# vpac_targetdb register map
Vendor: Texas Instruments
Registers are 32-bit, read-write, no defined reset value unless marked. A register's access mark holds for its fields unless they carry their own. Offsets are as the file gives them; [hi:lo] are bit positions; {n}, {i} and the like mark numbered series; 'fields as' and 'values as' point back to an identical list.

## VPAC (part 2 of 8) — Vision Pre-Processing Accelerator (VPAC)
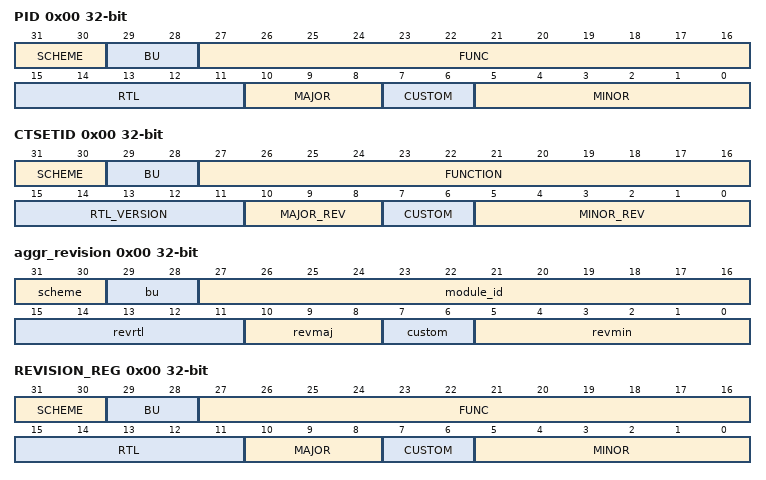
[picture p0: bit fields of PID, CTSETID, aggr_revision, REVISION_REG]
0x00 PID ro — VPAC PID
  [31:30] SCHEME — Used to distinguish between old scheme and new scheme. Spare bit to encode future schemes
  [29:28] BU — BU indicator
  [27:16] FUNC — Function indicates a software compatible module family.
  [15:11] RTL — RTL Version.
  [10:8] MAJOR — Major Revision.
  [7:6] CUSTOM — Indicates a special version for a particular device.
  [5:0] MINOR — Minor Revision.
0x00 REVISION ro
  [31:30] SCHEME
  [29:28] BU
  [27:16] FUNCTION — Module ID
  [15:11] RTLVER — RTL revisions
  [10:8] MAJREV — Major revision
  [7:6] CUSTOM — Custom revision
  [5:0] MINREV — Minor revision
{0x0+4i} pipeline_control_{i} (i=0..6) — Enable pipeline to activate all connected scheduler
  [0] pipe_en — Pipeline {i} enable, writing '1' activate pipeline , writing '0' during active pipeline is illegal and behavior is undefined, read '1' -> pipeline is active , read '0' -> pipeline is inactive
0x00 aggr_revision ro — Revision parameters
  [31:30] scheme
  [29:28] bu
  [27:16] module_id
  [15:11] revrtl — RTL version
  [10:8] revmaj — Major version
  [7:6] custom — Custom version
  [5:0] revmin — Minor version
0x00 CTSETID ro — CTSET identification register
  [31:30] SCHEME — Used to distinguish between old Scheme and current
  [29:28] BU — The value 10b designates this as Processor Business Unit IP
  [27:16] FUNCTION — Function : Indicates a Debug IP (0x2nn) and 0x80 is the identifier for CT-SET
  [15:11] RTL_VERSION — This field changes on bug fix, and resets to '0' when either Minor Revision or Major Revision field changes
  [10:8] MAJOR_REV — Major Revision. This field changes when there is a major feature change.
  [7:6] CUSTOM — Indicates a special version for a particular device. 0 if non-custom
  [5:0] MINOR_REV — Minor Revision. This field changes when features are scaled up or down
0x00 aggr_revision ro — Revision parameters
  fields as aggr_revision
0x00 REVISION_REG ro — LDC PID
  [31:30] SCHEME — Used to distinguish between old scheme and new scheme. Spare bit to encode future schemes
  [29:28] BU — BU indicatorDSPS ==> 0x0 WTBU ==> 0x1 Processors ==> 0x2
  [27:16] FUNC — Function indicates a software compatible module family. If there is no level of software compatibility a new FUNC number, and hence PID, should be assigned.
  [15:11] RTL — RTL Version. R as described in PDR with additional clarifications and definitions below. Must be easily ECO-able or controlled during fabrication. Ideally through a top level metal mask or e-fuse. This number is maintained/owned by IP design owner. RTL follows a numbering such as X.Y.R.Z which are explained in this table. R changes ONLY when: (1) PDS uploads occur which may have been due to spec changes (2) Bug fixes occur (3) Resets to '0' when X or Y changes. Design team has an internal 'Z' (customer invisible) number which increments on every drop that happens due to DV and RTL updates. Z resets to 0 when R increments.
  [10:8] MAJOR — Major Revision. X as described in PDR with additional clarifications/definitions below. This number is owned/maintained by IP specification owner. X is part of IP numbering X.Y.R.Z.X changes ONLY when: (1) There is a major feature addition. An example would be adding Master Mode to Utopia Level2. The Func field (or Class/Type in old PID format) will remain the same. X does NOT change due to: (1) Bug fixes (2) Change in feature parameters.
  [7:6] CUSTOM — Indicates a special version for a particular device. Consequence of use may avoid use of standard Chip Support Library (CSL) / Drivers. 0 if non-custom.
  [5:0] MINOR — Minor Revision. Y as described in PDR with additional clarifications/definitions below. This number is owned/maintained by IP specification owner. Y changes ONLY when: (1) Features are scaled (up or down). Flexibility exists in that this feature scalability may either be represented in the Y change or a specific register in the IP that indicates which features are exactly available. (2) When feature creeps from Is-Not list to Is list. But this may not be the case once it sees silicon - in which case X will change. Y does NOT change due to: (1) Bug fixes (2) Typos or clarifications (3) major functional/feature change/addition/deletion. Instead these changes may be reflected via R, S, X as applicable. Spec owner maintains a customer-invisible number 'S' which changes due to: (1) Typos/clarifications (2) Bug documentation. Note that this bug is not due to a spec change but due to implementation. Nevertheless, the spec tracks the IP bugs. An RTL release (say for silicon PG1.1) that occurs due to bug fix should document the corresponding spec number (X.Y.S) in its release notes.
0x00 status_param ro — The STATUS_PARAM register returns the LSE compile configuration parameters.
  [31:30] BYPASS_CH — Number of available input channel selection for loopback mode
  [29] OUT_SKIP_EN — Output Auto-Skip Enable
  [28] CORE_OUT_2D — 1D or 2D output addressing mode(2D if 1)
  [27:23] CORE_OUT_DW — Core Output Channel Data Width
  [22] LINE_SKIP_EN — Source Line Inc by 2 Supported (if 1)
  [21] BIT_AOFFSET — Source nibble offset address Supported (if 1)
  [20] HV_INSERT — H/VBLANK Insertion Supported (if 1)
  [19:17] PIX_MX_HT — Core_Input Pixel Matrix Height
  [16:12] CORE_DW — Core Input Data Bus Width
  [11:10] SL2_OUT_H3A_CH — Number of SL2 H3A Output Channels
  [9:6] SL2_OUT_CH — Number of SL2 Output Channels
  [5:3] SL2_IN_CH_THR — Number of Input Channels per thread
  [2] VPORT_THR — Number of VPORT input enabled
  [1:0] NTHR — Number of threads supported
0x00 LUT — dualy width conversion LUT
  [27:16] LUT_1 — Bank-1
  [11:0] LUT_0 — Bank-0
0x00 LUT — dualc width conversion LUT
  [27:16] LUT_1 — Bank-1
  [11:0] LUT_0 — Bank-0
0x00 RAM — mesh memory
  [31:0] MEM — Memory location
0x00 RAM access per field — y memory
  [23:0] MEM rw — Memory location
0x00 RAM access per field — cbcr memory
  [23:0] MEM rw — Memory location
0x00 aggr_revision ro — Revision parameters
  fields as aggr_revision
0x00 REVISION_REG ro — VISS PID
  fields as REVISION_REG
0x00 status_param ro — The STATUS_PARAM register returns the LSE compile configuration parameters.
  fields as status_param
0x00 GLBCE_CFG access per field — GLBCE Configuration Registers
  [0] SWRST rw — Reserved for this version for HW. This bit initiate software reset process
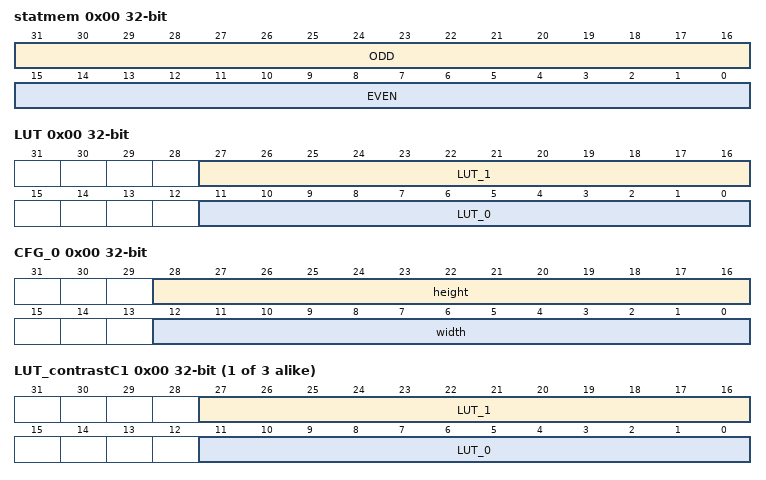
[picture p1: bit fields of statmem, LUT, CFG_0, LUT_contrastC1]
0x00 statmem — odd and even banks are combined for one 32-bit access
  [31:16] ODD — Odd bank
  [15:0] EVEN — Even bank
0x00 LUT — The LUT table contains the information used to reduce the pixle width to 12 from 13-16
  [27:16] lut_entry_hi — The upper LUT entry n+1.
  [11:0] lut_entry_lo — The lower LUT entry n+0.
0x00 CFG_0 access per field — The Control Register controls the input width and height of the module.
  [28:16] height rw — Height of the input image
  [12:0] width rw — Width of the input image
0x00 LUT_contrastC{i} access per field (i=1..3) — Memory for contrast C1
  [27:16] LUT_1 rw — Bank-1
  [11:0] LUT_0 rw — Bank-0
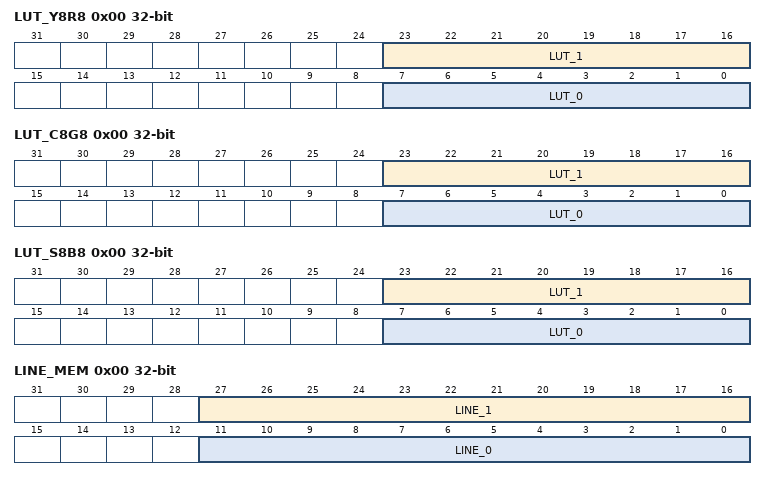
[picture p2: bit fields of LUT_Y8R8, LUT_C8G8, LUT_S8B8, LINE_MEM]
0x00 LUT_Y8R8 access per field — Memory for 12to8 LUT
  [23:16] LUT_1 rw — Bank-1
  [7:0] LUT_0 rw — Bank-0
0x00 LUT_C8G8 access per field — Memory for 12to8 LUT
  [23:16] LUT_1 rw — Bank-1
  [7:0] LUT_0 rw — Bank-0
0x00 LUT_S8B8 access per field — Memory for 12to8 LUT
  [23:16] LUT_1 rw — Bank-1
  [7:0] LUT_0 rw — Bank-0
0x00 HIST access per field — Memory for Histogram
  [19:0] HIST_VAL rw — Bank-0
0x00 LINE_MEM access per field — Memory for 2 lines of yuv444to420
  [27:16] LINE_1 rw, [11:0] LINE_0 rw
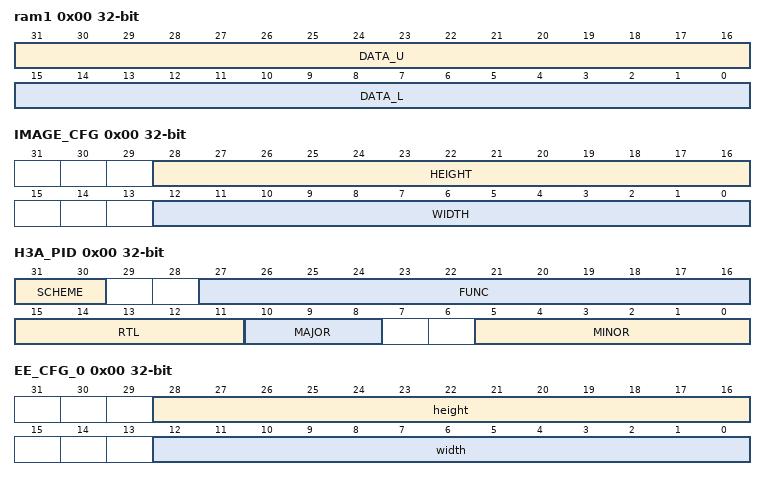
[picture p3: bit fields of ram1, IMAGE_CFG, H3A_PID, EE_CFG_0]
0x00 ram1 — Input image width and height.
  [31:16] DATA_U — reserved
  [15:0] DATA_L — reserved
0x00 ram1 — Input image width and height.
  [31:16] DATA_U — reserved
  [15:0] DATA_L — reserved
0x00 ram1 — Input image width and height.
  [31:16] DATA_U — reserved
  [15:0] DATA_L — reserved
0x00 ram1 — Input image width and height.
  [31:16] DATA_U — reserved
  [15:0] DATA_L — reserved
0x00 ram1 — Input image width and height.
  [25:16] DATA_U — reserved
  [9:0] DATA_L — reserved
0x00 ram1 — Input image width and height.
  [28:0] DATA — reserved
0x00 ram1 — Input image width and height.
  [31:0] DATA — reserved
0x00 ram1 — Input image width and height.
  [31:0] DATA — reserved
0x00 IMAGE_CFG access per field — Input image width and height.
  [28:16] HEIGHT rw — image height
  [12:0] WIDTH rw — image width
0x00 H3A_PID ro — Peripheral Revision and Class Information
  [31:30] SCHEME — PID scheme type
  [27:16] FUNC — PID func revision
  [15:11] RTL — PID rtl revision
  [10:8] MAJOR — PID major revision
  [5:0] MINOR — PID minor revision
0x00 ram1 — Input image width and height.
  [19:0] DATA — reserved
0x00 ram1 — Input image width and height.
  [31:0] DATA — reserved
0x00 DBG_MEM — Warning: reading or writing this MMR during operation will corrupt processing resulting in bad output data and will result in error interrupt firing. diagnostic rd/wr access to embedded RAM, for possible purpose of debugging failures
  [31:0] data — Adr range selects which RAM address to index. (Wr or rd beyond populated RAM adr result in non productive cycles and rd returns zero)
0x00 EE_CFG_0 — The Control Register controls the input width and height of the module.
  [28:16] height — Height of the input image
  [12:0] width — Width of the input image
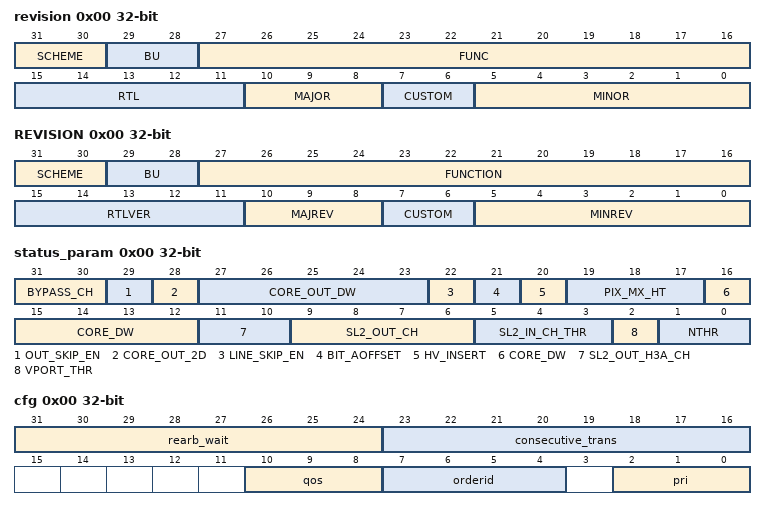
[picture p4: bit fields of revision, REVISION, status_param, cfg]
0x00 revision ro — The REVISION Register contains the major and minor revisions for the VPAC MSC HWA module.
  [31:30] SCHEME — Used to distinguish between old scheme and new scheme. Spare bit to encode future schemes
  [29:28] BU — BU indicatorDSPS ==> 0x0 WTBU ==> 0x1 Processors ==> 0x2
  [27:16] FUNC — Function indicates a software compatible module family. If there is no level of software compatibility a new FUNC number, and hence PID, should be assigned.
  [15:11] RTL — RTL Version. R as described in PDR with additional clarifications and definitions below. Must be easily ECO-able or controlled during fabrication. Ideally through a top level metal mask or e-fuse. This number is maintained/owned by IP design owner. RTL follows a numbering such as X.Y.R.Z which are explained in this table. R changes ONLY when : (1) PDS uploads occur which may have been due to spec changes (2) Bug fixes occur (3) Resets to '0' when X or Y changes. Design team has an internal 'Z' (customer invisible) number which increments on every drop that happens due to DV and RTL updates. Z resets to 0 when R increments.
  [10:8] MAJOR — Major Revision. X as described in PDR with additional clarifications/definitions below. This number is owned/maintained by IP specification owner. X is part of IP numbering X.Y.R.Z.X changes ONLY when: (1) There is a major feature addition. An example would be adding Master Mode to Utopia Level2. The Func field (or Class/Type in old PID format) will remain the same. X does NOT change due to: (1) Bug fixes (2) Change in feature parameters.
  [7:6] CUSTOM — Indicates a special version for a particular device. Consequence of use may avoid use of standard Chip Support Library (CSL) / Drivers. 0 if non-c ustom.
  [5:0] MINOR — Minor Revision. Y as described in PDR with additional clarifications/definitions below. This number is owned/maintained by IP specification owne r. Y changes ONLY when: (1) Features are scaled (up or down). Flexibility exists in that this feature scalability may either be represented in the Y change or a specific register in the IP that indica tes which features are exactly available. (2) When feature creeps from Is-Not list to Is list. But this may not be the case once it sees silicon - in which case X will change. Y does NOT change due to : (1) Bug fixes (2) Typos or clarifications (3) major functional/feature change/addition/deletion. Instead these changes may be reflected via R, S, X as applicable. Spec owner maintains a customer-invisible number 'S' which changes due to: (1) Typos/clarifications (2) Bug documentation. Note that this bug is not due to a spec change but due to implementation. Nevertheless, the spec tracks the I P bugs. An RTL release (say for silicon PG1.1) that occurs due to bug fix should document the corresponding spec number (X.Y.S) in its release notes.
0x00 status_param ro — The STATUS_PARAM register returns the LSE compile configuration parameters.
  fields as status_param
0x00 REVISION ro — The Revision Register contains the major and minor revisions for the module.
  [31:16] modid — Module ID field
  [15:11] revrtl — RTL revision. Will vary depending on release.
  [10:8] revmaj — Major revision
  [7:6] custom
  [5:0] revmin — Minor revision
0x00 status_param ro — The STATUS_PARAM register returns the LSE compile configuration parameters.
  fields as status_param
0x00 dru_pid ro — Peripheral ID Register
  [31:0] revision — PID Revision
0x00 dru_shared_evt_set access per field — DRU Shared Event Set Register
  [0] prot_err wo — Set the Prot Error event
0x00 cfg access per field — Configuration Register for Queue 0
  [31:24] rearb_wait rw — This is the number of commands that will be sent by other queues before allowing the queue to arbitrate again for the right to send commands. This is only started when a queue exhausted its consecutive trans count.
  [23:16] consecutive_trans rw — This is the number of consecutive transactions that will be sent before allowing another queue of equal level to arbitrate to send commands. This is the maximum number of commands that it can send. If the queue has any delays such as virtual address lookup then the arbitration will be forced regardless of the number of commands.
  [10:8] qos rw — This configures the QOS for QUEUE0. This should only be set for fixed priority queues and the lower queue should have the lower QoS.
  [7:4] orderid rw — This configures the orderid for QUEUE0.
  [2:0] pri rw — This configures the priority for QUEUE0. This will be the priority that will be presented on the External bus for all commands from this queue.
0x00 dru_pid ro — Peripheral ID Register
  [31:0] revision — PID Revision
0x00 dru_shared_evt_set access per field — DRU Shared Event Set Register
  [0] prot_err wo — Set the Prot Error event
0x00 cfg access per field — Configuration Register for Queue 0
  fields as cfg
0x00 pid ro — The Revision Register contains the major and minor revisions for the module.
  [31:30] scheme — PID register scheme
  [29:28] bu — Business Unit: 10 = Processors
  [27:16] func — Module ID
  [15:11] rtl — RTL revision. Will vary depending on release.
  [10:8] major — Major revision
  [7:6] custom
  [5:0] minor — Minor revision
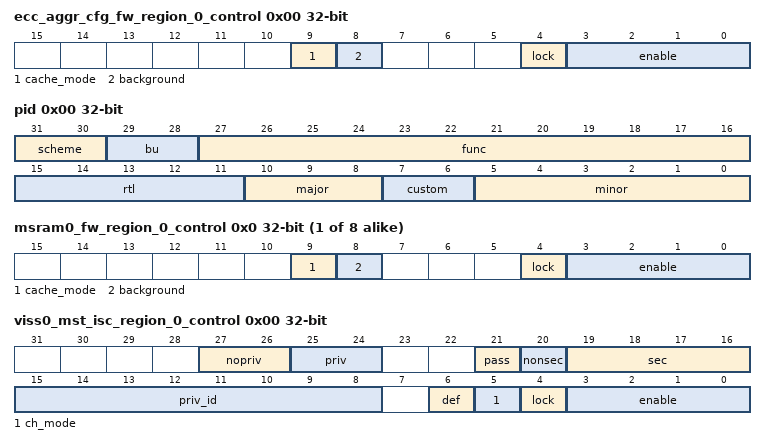
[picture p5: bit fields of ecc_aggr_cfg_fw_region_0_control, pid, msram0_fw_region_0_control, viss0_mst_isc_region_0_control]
0x00 ecc_aggr_cfg_fw_region_0_control — The FW Region 0 Control Register defines the control fields for the slave ksdw_ecc_aggr.cfg region 0 firewall.
  [9] cache_mode — Cache mode for region. Set to 1 to check cache permissions. Set to 0 to ignore cache permissions.
  [8] background — Background enable for region. There can be 1 backgroun region per FW and foreground regions can have overlapping addresses only with the background region.
  [4] lock — Lock region. Once set region values cannot be modified.
  [3:0] enable — Enable region. A value of 0xA enables, others disable.
0x00 pid ro — The Revision Register contains the major and minor revisions for the module.
  fields as pid
{0x0+0x20*i} msram0_fw_region_{i}_control (i=0..7) — The FW Region {i} Control Register defines the control fields for the slave ksbus_msram0.slv region {i} firewall.
  fields as ecc_aggr_cfg_fw_region_0_control
0x00 viss0_mst_isc_region_0_control access per field — The ISC Region 0 Control Register defines the control fields for the master .viss0_mst region 0 ISC.
  [27:26] nopriv rw — Clear output priv attribute. If each bit is set then the outgoing priv bit is cleared.
  [25:24] priv rw — Set outgoing priv attribute. If each bit is set then the outgoing priv bit is set.
  [21] pass rw — No privID replacement, pass through value.
  [20] nonsec rw — Make outgoing non-secure.
  [19:16] sec rw — Make outgoing secure. A value of 0xA enables, others disable.
  [15:8] priv_id rw
  [6] def ro — Default region indication. The default region is used when all other regions do not match.
  [5] ch_mode rw — Enable channel mode to match region to a chanid value. Otherwise use address mode to match region to an address range.
  [4] lock rw — Lock region. Once set the region values cannot be modified.
  [3:0] enable rw — Enable region. A value of 0xA enables, others disable.
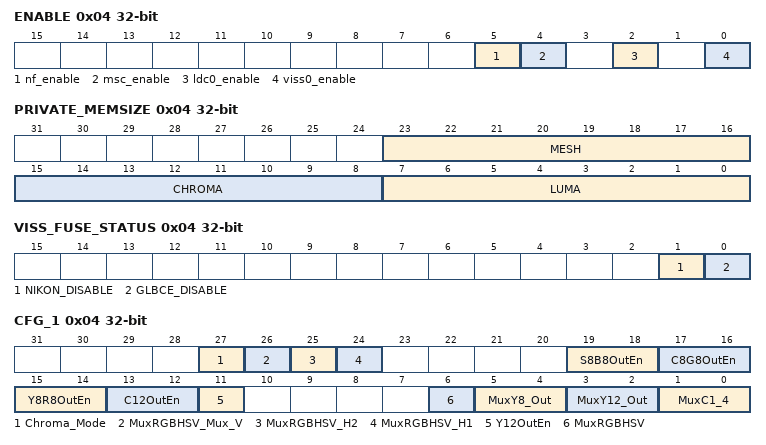
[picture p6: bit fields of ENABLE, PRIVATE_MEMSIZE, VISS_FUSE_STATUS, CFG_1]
0x04 ENABLE — VPAC accelerators Enable; used in clock gating accelerator when disabled. NOT SUPPORTED IN current VERSION
  [5] nf_enable — '1' --> nf is enabled , '0' --> nf is disabled
  [4] msc_enable — '1' --> msc is enabled , '0' --> msc is disabled
  [2] ldc0_enable — '1' --> ldc0 is enabled , '0' --> ldc0 is disabled
  [0] viss0_enable — '1' --> viss0 is enabled , '0' --> viss0 is disabled
0x04 PRIVATE_MEMSIZE ro — Memory size mentioned is for both ping and pong combined. Error interrupts are generated based on the memory size available.
  [23:16] MESH — Mesh Private pixel memory size in KBytes
  [15:8] CHROMA — Chroma Private pixel memory size in KBytes
  [7:0] LUMA — Luma Private pixel memory size in KBytes
0x04 status_error — The STATUS_ERROR register returns the LSE error status.
  [14:8] vm_wr_err — VBUSM I/F Last Write Error Status [14:11] Write Channel Number [10:8] VBUSM write error status
0x04 VISS_FUSE_STATUS ro — Register captures the Fuse control status. Shouldn't be captured into TRM
  [1] NIKON_DISABLE — Availability of NIKON specific feature HW in H3A. '0' -> Nikon features are available '1' -> Nikon features are not available
  [0] GLBCE_DISABLE — Availability GLBCE HW. '0' -> GLBCE function HW is available '1' -> GLBCE function HW is not available
0x04 status_error — The STATUS_ERROR register returns the LSE error status.
  [26:16] vport_in_err — VPORT_CAL Input Error Status Protocol Errors [26] VS without HS [25] VE without HE [24] VS-VS (missing VE) Error [23] HS-HS (missing HE) Error [22] HE-HE (missing HS) Error [21] VE-VE (missing VS) Error Frame Size Errors [20] Frame Skipped during Error Handling [19] Long Frame detected [18] Short Frame detected [17] Long Line detected [16] Short Line Detected
  [14:8] vm_wr_err — VBUSM I/F Last Write Error Status [14:11] Write Channel Number [10:8] VBUSM write error status
  [4:0] vm_rd_err — VBUSM I/F Last Read Error Status [4:3] Read Channel Number [2:0] VBUSM read error status
0x04 GLBCE_MODE access per field — GLBCE Mode Control register
  [0] OST rw — One shot mode or continuous mode One shot mode turns itself off after each frame Note that this bit only controls the enable signal, and does not revert the statistics to the default status To revert the cache content to the default status, you either need to SW reset GLBCE module, or load the default value from SDRAM to cache memory To perform the latter option, default cache table needs to be copied to SDRAM before hand
0x04 CFG_1 access per field — Configuration Register for top level data flow
  [27] Chroma_Mode rw — Mux for 422/420 (0:420 Chroma ,1: 422 Chroma)
  [26] MuxRGBHSV_Mux_V rw — Mux for V calculation (0:Select non WB corrected data ,1: Select WB corrected data)
  [25] MuxRGBHSV_H2 rw — Mux for S/V calculation (0:Select B,1: Select Max(RGB))
  [24] MuxRGBHSV_H1 rw — Mux for S/V calculation (0:Select R,1: Select Min(RGB))
  [19:18] S8B8OutEn rw — '0': Disable All , '1': S8 enable, 2:B8 enable, 3:C4 enable
  [17:16] C8G8OutEn rw — '0': Disable All , '1': C8 enable, 2:G8 enable, 3:C3 enable
  [15:14] Y8R8OutEn rw — '0': Disable all , '1': Y8 enable, 2:R8 enable, 3:C2 enable
  [13:12] C12OutEn rw — '0': Disable all , '1': C12 enable, '2': C1 enable
  [11] Y12OutEn rw — '0': Disable Y12 output, '1': Enable Y12 output
  [6] MuxRGBHSV rw — Input Select for RGBHSV (0:In after Contrast,1: In before Contrast)
  [5:4] MuxY8_Out rw — Mux for Y-8 Output (0:MuxC1_4, 1:RGB2YUV, 2:RGB2HSV)
  [3:2] MuxY12_Out rw — Mux for Y-12 Output (0:MuxC1_4, 1:RGB2YUV, 2:RGB2HSV, 3:C1 enable)
  [1:0] MuxC1_4 rw — Mux for selecting C input (0:C0, 1:C1, 2:C2, 3:C3)
0x04 SHADOW_CFG — shadow configuration
  [0] LUT3_SHDW_EN — use LUT2 ram as LUT table for LUT3 processing
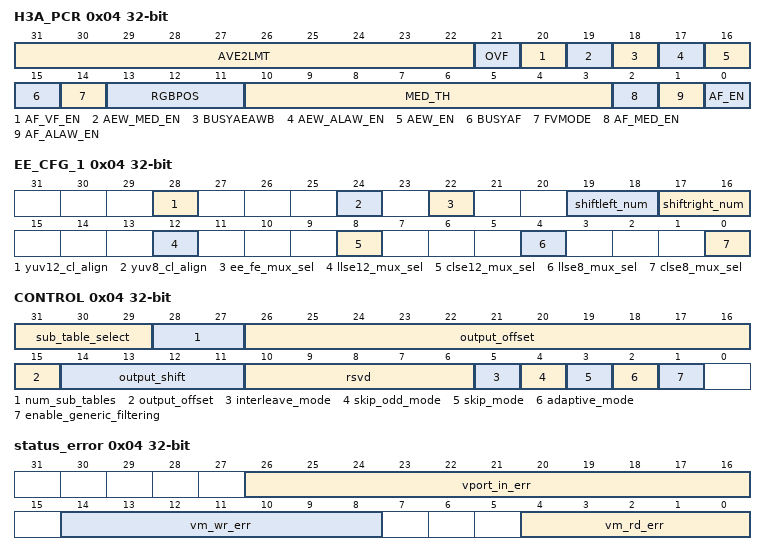
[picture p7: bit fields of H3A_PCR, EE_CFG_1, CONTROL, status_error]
0x04 H3A_PCR access per field — Peripheral Control Register
  [31:22] AVE2LMT rw — AE/AWB Saturation Limit This is the value that all sub sampled pixels in the AE/AWB engine are compared to If the data is greater or equal to this data then the block is considered saturated
  [21] OVF rw — H3A module overflow status bit If the H3A module overflows it will keep sending data The software can read this status bit during vertical blanking period to ensure that no overflow happened while writing out the data to SDRAM There is also an interrupt which can be used to monitor this
  [20] AF_VF_EN rw — AF Vertical Focus Enable
  [19] AEW_MED_EN rw — AE/AWB Median filter Enable If the median filter is enabled, then the 1st 2 and last 2 pixels in the frame are not filtered
  [18] BUSYAEAWB ro — Busy bit for AE/AWB
  [17] AEW_ALAW_EN rw — AE/AWB A-law Enable
  [16] AEW_EN rw — AE/AWB enable
  [15] BUSYAF ro — Busy bit for AF
  [14] FVMODE rw — Focus Value Accumulation Mode
  [13:11] RGBPOS rw — Red, Green, and blue pixel location in the AF windows RGBPOS[0]: GR and GB as Bayer pattern RGBPOS[1]: RG and GB as Bayer pattern RGBPOS[2]: GR and BG as Bayer pattern RGBPOS[3]: RG and BG as Bayer pattern RGBPOS[4]: GG and RB as custom pattern RGBPOS[5]: RB and GG as custom pattern 6 and 7 are reserved This Value is only used if VF is disabled
  [10:3] MED_TH rw — Median filter threshold
  [2] AF_MED_EN rw — Auto Focus Median filter Enable If the median filter is enabled, then the 1st 2 and last 2 pixels in the frame are not in the valid region Therefore the paxel start/end and IIR filter start positions should not be set within the 1st and last 2 pixels
  [1] AF_ALAW_EN rw — AF A-law table enable
  [0] AF_EN rw — AF enable
0x04 dbg — Diagnostic Register Control
  [5:0] ram_mux_cfg — Diagnostic Rd Wr access to Embedded RAM Selector Mux. This bit controls the mux select or which RAM and which section of that RAM are assessed via the VBUSP read of RAM. (This MMR is not shadowed)
0x04 EE_CFG_1 — The CEE route config Register controls the routing of trafic through and around the EE.
  [28] yuv12_cl_align — Enables the alignment of the Chroma and Luma for the yuv12 stream. The aligner can align the Chroma and Luma +-19 pixel clocks. 1: Enable alignment. 0: Pass Chroma and Luma as they arrive.
  [24] yuv8_cl_align — Enables the alignment of the Chroma and Luma for the yuv8 stream. The aligner can align the Chroma and Luma +-19 pixel clocks. 1: Enable alignment. 0: Pass Chroma and Luma as they arrive.
  [22] ee_fe_mux_sel — Selects which data stream to pass through the EE block. 0: Selects the yuv12 stream. 1: selects the yuv8 stream.
  [19:18] shiftleft_num — Sects the amount to shift left the incoming pixel to the EE block. 0: No Shift. 1: Shift by 2. 2: Shift by 4. 3: Reserved for future expansion.
  [17:16] shiftright_num — Sects the amount to shift right the outgoing pixel from the EE block. 0: No Shift. 1: Shift by 2. 2: Shift by 4. 3: Reserved for future expansion.
  [12] llse12_mux_sel — Selects Luma stream for the yuv12 output. 0: Bypass EE block. 1: Use EE Luma Output.
  [8] clse12_mux_sel — Selects Chroma stream for the yuv12 output. 0: Bypass EE block. 1: Use EE Chroma Output.
  [4] llse8_mux_sel — Selects Luma stream for the yuv8 output. 0: Bypass EE block. 1: Use EE Luma Output.
  [0] clse8_mux_sel — Selects Chroma stream for the yuv8 output. 0: Bypass EE block. 1: Use EE Chroma Output.
0x04 control — The CONTROL Register allows the CPU to control various aspects of the module.
  [0] msc_enable — MSC Core Enable: Enables the MSC HWA.(Must be enabled even when MSC is strictly in the loopback-only mode. Individual resizing filter is enabled only when the output buffer associated with the filter is enabled in the LSE configuration.) 0: Disable 1: Enable
0x04 status_error — The STATUS_ERROR register returns the LSE error status.
  [14:8] vm_wr_err — VBUSM I/F Last Write Error Status [14:11] Write Channel Number [10:8] VBUSM write error status
  [4:0] vm_rd_err — VBUSM I/F Last Read Error Status [4:3] Read Channel Number [2:0] VBUSM read error status
0x04 CONTROL access per field — This contains parameters to control NF Core
  [31:29] sub_table_select rw — Defines which sub table is used statically. Only valid when adaptive_mode is disabledThis allows the SW to statically define which sub table to use throughout the frame. SW must set this before the first line of the frame 0 = sub Table 0 selected 1 = sub Table 1 selected . 7 = sub Table 7 selected
  [28:27] num_sub_tables rw — Defines the number of sub-tables 0 = 1 table 1 = 2 sub tables 2 = 4 sub tables 3 = 8 sub tables
  [26:15] output_offset rw — unsigned offset value to added to output after shifting and before clipping
  [14:11] output_shift rw — Signed 4 bit (24 is added before using it inside IP)
  [10:6] rsvd ro — Always read as 0. Writes have no affect
  [5] interleave_mode rw — Interleave Mode. 0 = Disabled 1 = Enabled
  [4] skip_odd_mode rw — Skip Odd Mode. 0 = Disabled 1 = Enabled
  [3] skip_mode rw — Skip Mode. 0 = Disabled 1 = Enabled
  [2] adaptive_mode rw — Defines what controls the selection of the sub table. 0 = Bi-lateral filtering Adaptive mode is Disabled and sub_table_select defines which sub table is used 1 = Bi-lateral filtering Adaptive mode is Enabled and the 4x4 avg is used to determine which sub table is used
  [1] enable_generic_filtering rw — Filter mode, 0=> Bi-lateral filtering, 1= Generic 2D Filtering
0x04 status_error — The STATUS_ERROR register returns the LSE error status.
  [14:8] vm_wr_err — VBUSM I/F Last Write Error Status [14:11] Write Channel Number [10:8] VBUSM write error status
  [4:0] vm_rd_err — VBUSM I/F Last Read Error Status [4:3] Read Channel Number [2:0] VBUSM read error status
0x04 destination_id — The Destination ID Register defines the destination ID value for error messages.
  [7:0] dest_id — The destination ID.
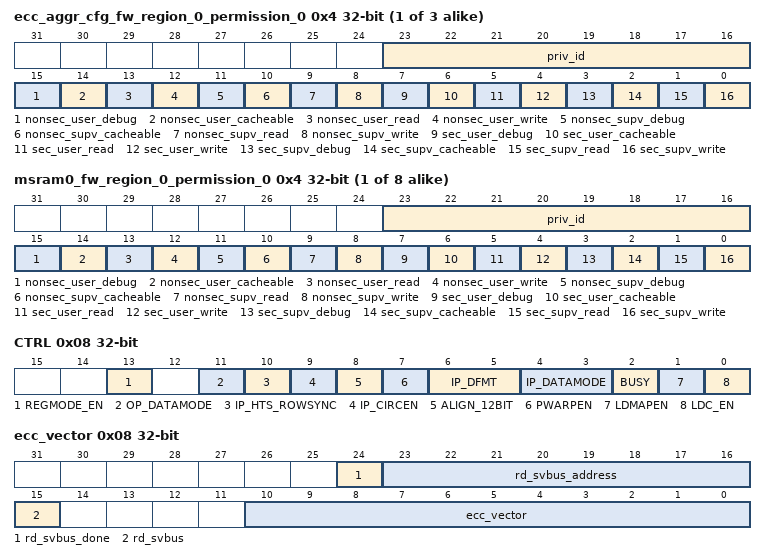
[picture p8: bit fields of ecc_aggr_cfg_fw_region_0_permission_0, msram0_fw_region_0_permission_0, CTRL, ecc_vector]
{0x4+4i} ecc_aggr_cfg_fw_region_0_permission_{i} (i=0..2) — The FW Region 0 Permission {i} Register defines the permissions for the slave ksdw_ecc_aggr.cfg region 0 firewall.
  [23:16] priv_id — Allowed privid.
  [15] nonsec_user_debug — Non-secure user debug allowed.
  [14] nonsec_user_cacheable — Non-secure user cacheable allowed.
  [13] nonsec_user_read — Non-secure user read allowed.
  [12] nonsec_user_write — Non-secure user write allowed.
  [11] nonsec_supv_debug — Non-secure supervisor debug allowed.
  [10] nonsec_supv_cacheable — Non-secure supervisor cacheable allowed.
  [9] nonsec_supv_read — Non-secure supervisor read allowed.
  [8] nonsec_supv_write — Non-secure supervisor write allowed.
  [7] sec_user_debug — Secure user debug allowed.
  [6] sec_user_cacheable — Secure user cacheable allowed.
  [5] sec_user_read — Secure user read allowed.
  [4] sec_user_write — Secure user write allowed.
  [3] sec_supv_debug — Secure supervisor debug allowed.
  [2] sec_supv_cacheable — Secure supervisor cacheable allowed.
  [1] sec_supv_read — Secure supervisor read allowed.
  [0] sec_supv_write — Secure supervisor write allowed.
0x04 destination_id — The Destination ID Register defines the destination ID value for error messages.
  [7:0] dest_id — The destination ID.
{0x4+0x20*i} msram0_fw_region_{i}_permission_0 (i=0..7) — The FW Region {i} Permission 0 Register defines the permissions for the slave ksbus_msram0.slv region {i} firewall.
  fields as ecc_aggr_cfg_fw_region_0_permission_0
0x08 CG_ENABLE_OVERRIDE — Register to override the root clock gating done in VPAC to reduce power.By default these bits are 0. it should be set to 1 only when we encounter some silicon bug. NOT SUPPORTED in current Version
  [0] cg_override — clock gating override
0x08 ecc_vector
  [24] rd_svbus_done — Status to indicate if read on serial VBUS is complete, write of any value will clear this bit.
  [23:16] rd_svbus_address — Read address
  [15] rd_svbus — Write 1 to trigger a read on the serial VBUS
  [10:0] ecc_vector — Value written to select the corresponding ECC RAM for control or status
0x08 ecc_vector
  fields as ecc_vector
0x08 CTRL access per field — Control Register to Enable/Disable and select modes of operation
  [13] REGMODE_EN rw — Enables for Frame division into multiple regions. Needs to be enabled only when more than one region per frame. 0 - Disable 1 - Enable When enabled, LDC provides option to configure independent block size parameters for each region
  [11] OP_DATAMODE rw — Output Pixel Data Mode; Used when input is YUV422 mode. 0: YUV422 mode 1: convert to YUV420 output data;
  [10] IP_HTS_ROWSYNC rw — Enables control of Input Fetch with HTS at Block Row level. 0 - Disable 1 - Enable When enabled, input fetch of first block in row is gated with corresponding HTS Tstart number. This allows 'synchronization between VISS and LDC' or/and 'mesh data sync at row level'. This can't be enabled when Region mode is enabled
  [9] IP_CIRCEN rw — Enables circular addressing mode on input pixel fetch. 0 - Disable circular addressing for input data. 1 - Enable circular addressing.
  [8] ALIGN_12BIT rw — Alignment of 12-bit pixel in 420 16-bit unpacked mode on input pixel data. 0 - LSB Aligned 1 - MSB Aligned
  [7] PWARPEN rw — Perspective warp transform Enable. Set to 1 to enable use of PWARP_GH.G and PWARP_GH.H
  [6:5] IP_DFMT rw — Input Pixel Data Format 0: 8-bit format 1: 12-bit packed format 2: 12-bit unpacked format(LSB Aligned) 3: Reserved
  [4:3] IP_DATAMODE rw — Input Pixel Data Mode 0: YUV422 Input data 1: YUV420_Y Luma Data Only 2: YUV420 Data 3: YUV420_UV Chroma Data Only. Program frame/block size as in YUV420 mode
  [2] BUSY ro — Idle/Busy Status, 0: Idle 1: Busy Set on hts_init when LDC_EN is high, cleared on Frame completion
  [1] LDMAPEN rw — Distortion Back Mapping Enable. 1: Enabled 0: Disabled
  [0] LDC_EN rw — Write 1 to Start LDC function. Auto cleared by HW at the end of Frame completion.
0x08 status_idle_mode ro — The STATUS_IDLE_MODE register returns IDLE status of LSE VBUSM port and in/output channels - 0: IDLE 1: ACTIVE
  [15:12] lse_out_chan — Output Channel[3:0] Status
  [1] vm_wr_port — SL2 vbusm I/F Write Port Status
0x08 ecc_vector
  fields as ecc_vector
0x08 VISS_LINEMEM_SIZE ro — Captures the no. of pixels per line supported by the VISS
  [13:0] LINEMEM_SZ — No. of pixels per line supported by the VISS HWAs Memories
0x08 status_idle_mode ro — The STATUS_IDLE_MODE register returns IDLE status of LSE VBUSM port and in/output channels - 0: IDLE 1: ACTIVE
  [24] lse_out_h3a_chan — Output H3A Channel Status
  [16:12] lse_out_chan — Output Channel[4:0] Status
  [11] vport_in_chan — CAL I/F Vport Input Cahnnel Status
  [6:4] lse_in_chan — Input Channel[2:0] Status
  [1] vm_wr_port — SL2 vbusm I/F Write Port Status
  [0] vm_rd_port — SL2 vbusm I/F Read Port Status
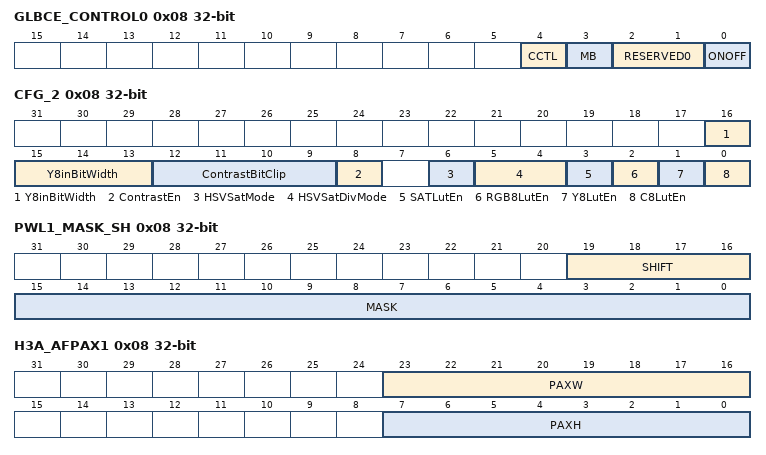
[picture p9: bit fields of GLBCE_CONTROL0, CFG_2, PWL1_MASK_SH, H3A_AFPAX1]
0x08 GLBCE_CONTROL0 access per field — GLBCE Control Register 0 (control_0)
  [4] CCTL ro — Color Control [CCTL] - Enabling this processing will result in more accurate colors processing The color correction algorithm is required on gamma corrected sources It reduces the saturation in dark areas when they are being amplified, and saturates bright parts when they get darker. This bit is reserved and tied zero in this version. 0b: Disable color correction 1b: Enable color correction
  [3] MB rw — Max Bayer Type- Use this bit to select the algorithm used for calculating intensity 0b: Algorithm 1 1b: Algorithm 2 [Recommended]
  [2:1] RESERVED0 ro — These bits are read only Controls the storage of image sensor RAW data in memory This bit is loaded with the timing of the internal VD signal: it becomes active starting at the lead of the VD signal that comes after 1 is written in this bit
  [0] ONOFF rw — GLBCE On/Off - This bit turns GLBCE processing ON and OFF When GLBCE is OFF, the video data passes to the output without any changes Disabling GLBCE using this bit is equivalent to setting the Strength parameter to 0 Many internal modules run in idle mode when this bit is 0 The Latency Delays between the input and the output signals are the same in both ON and OFF modes 0b: Disable GLBCE processing 1b: Enable GLBCE processing
0x08 CFG_2 access per field — Configuration Register-2
  [16:13] Y8inBitWidth rw — Bitwidth of input to 12to8 module (Y8) for shift(Program as 12 or lower)
  [12:9] ContrastBitClip rw — Clip Value set as 2^ContrastBitClip -1
  [8] ContrastEn rw — 0:Disable, 1: Enable Contrast
  [6] HSVSatMode rw — 0:Max(RGB) - Min(RGB), 1:Sum(RGB) - Min(RGB)
  [5:4] HSVSatDivMode rw — 0:One, 1:Max(RGB), 2: 4095 -V, 3:Sum(RGB)
  [3] SATLutEn rw — '1':Use LUT, '0':Use shift
  [2] RGB8LutEn rw — '1':Use LUT, '0':Use shift
  [1] Y8LutEn rw — '1':Use LUT, '0':Use shift
  [0] C8LutEn rw — '1':Use LUT, '0':Use shift
0x08 PWL1_MASK_SH access per field — Long frame PWL mask and shift values
  [19:16] SHIFT rw — number of right shift
  [15:0] MASK rw — mask bit pattern
0x08 H3A_AFPAX1 access per field — Setup for the AF Engine Paxel Configuration
  [23:16] PAXW rw — AF Engine Paxel Width The width of the paxel is the value of this register plus 1 multiplied by 2 The minimum width is 16 pixels if pixel clock is or less of the vpss clock If pixel clock is equal to vpss clock the minimum width is 32 pixels * This value is shadowed and latched on the rising edge of VSYNC
  [7:0] PAXH rw — AF Engine Paxel Height The height of the paxel is the value of this register plus 1 multiplied by 2 with a final value of 2-256 [even] * This value is shadowed and latched on the rising edge of VSYNC
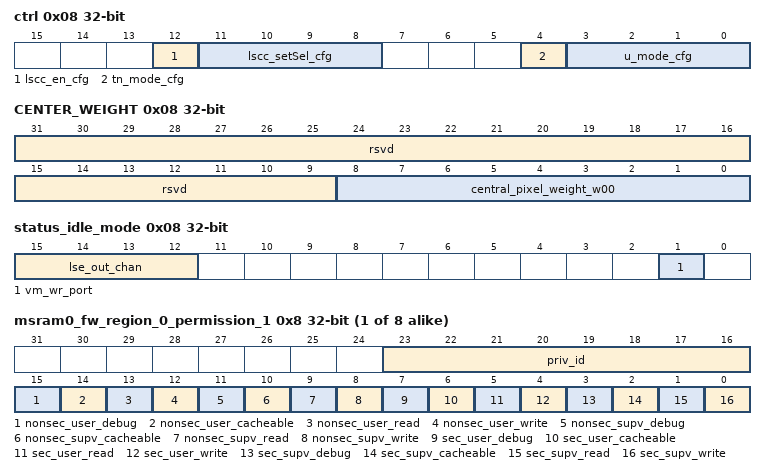
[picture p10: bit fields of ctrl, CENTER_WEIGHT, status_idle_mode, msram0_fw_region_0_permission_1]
0x08 ctrl — All modes are set here
  [12] lscc_en_cfg — enable Lens Shading Correction Compensation. When disabled, implments a unity gain
  [11:8] lscc_setSel_cfg — bit per BAYER color component indicating which of two sets of 16 segment PWL Curve to use for LSCC. 0: use set0 1: use set1
  [4] tn_mode_cfg — single bit controlling T_n calculation 0: use u_mode bits to indicate which LL2 to average and which bits to keep independent without averaging 1: independent no averaging
  [3:0] u_mode_cfg — bit per BAYER color component indicating Decomp sub component 0: average with others 1: independent color component do not average for calculation of U Suppress. bit[0]:color 0 at (v=0, h=0) bbit[1]:color 1 at (v=0, h=1)bbit[2]:color 2 at (v=1, h=0)bbit[3]:color 3 at (v=1, h=1)
0x08 EE_ENABLE — The EE Enable register control the internal bypass of the EE block.
  [0] yee_enable
0x08 status_idle_mode ro — The STATUS_IDLE_MODE register returns IDLE status of LSE VBUSM port and in/output channels - 0: IDLE 1: ACTIVE
  [21:12] lse_out_chan — Output Channel[9:0] Status
  [5:4] lse_in_chan — Input Channel[1:0] Status
  [1] vm_wr_port — SL2 vbusm I/F Write Port Status
  [0] vm_rd_port — SL2 vbusm I/F Read Port Status
0x08 CENTER_WEIGHT access per field — Contain center weight parameter
  [31:9] rsvd ro — Always read as 0. Writes have no affect
  [8:0] central_pixel_weight_w00 rw — Central pixel weight, 8 bit unsigned in Bi-lateral filtering, 9 bit signed in Generic 2D Filtering
0x08 status_idle_mode ro — The STATUS_IDLE_MODE register returns IDLE status of LSE VBUSM port and in/output channels - 0: IDLE 1: ACTIVE
  [12] lse_out_chan — Output Channel[0:0] Status
  [4] lse_in_chan — Input Channel[0:0] Status
  [1] vm_wr_port — SL2 vbusm I/F Write Port Status
  [0] vm_rd_port — SL2 vbusm I/F Read Port Status
0x08 dru_capabilities ro — DRU Capabilities: Lists the capabilities of the channel for TR TYPE and formatting functions
  [46:43] sectr — Maximum second TR function that is supported
  [42:39] dfmt — Maximum data reformatting function that is supported
  [38:35] eltype — Maximum element type value that is supported
  [34:32] amode — The maximum AMODE that is supported. If AMODE is supported then DIR field must be supported for that AMODE.
  [31:20] rsvd_conf_spec — Reserved for Configuration Specific Features. This implementation has no configuration specific features.
  [19] global_trig — Global Triggers 0 and 1 are supported
  [18] local_trig — Dedicated Local Trigger is supported
  [17] eol — EOL Field is supported
  [16] trstatic — STATIC Field is supported
  [n] type{n} (n=0..15) — Type {n} TR is supported
0x08 dru_capabilities ro — DRU Capabilities: Lists the capabilities of the channel for TR TYPE and formatting functions
  fields as dru_capabilities
{0x8+0x20*i} msram0_fw_region_{i}_permission_1 (i=0..7) — The FW Region {i} Permission 1 Register defines the permissions for the slave ksbus_msram0.slv region {i} firewall.
  fields as ecc_aggr_cfg_fw_region_0_permission_0
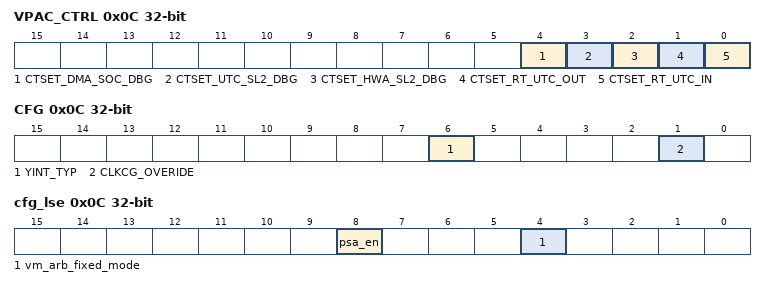
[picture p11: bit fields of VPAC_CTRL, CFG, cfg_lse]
0x0C VPAC_CTRL — Register to control and do event selection for VPAC module
  [4] CTSET_DMA_SOC_DBG — select config for CTSET[206:175] '0' --> select UTC1 (NRT) utc1_ctset_intr[31:0] , '1' --> Select ldc0_rd,utc1_ext,utc0_ext master ports (sreq,rreq,creq stall,valid creq)
  [3] CTSET_UTC_SL2_DBG — select config for CTSET[254:239] '0' --> select ext_ctset_event[15:0] , '1' --> Select utc1_wr,utc1_rd,utc0_wr,utc0_rd master ports (sreq,rreq,creq stall,valid creq)
  [2] CTSET_HWA_SL2_DBG — select config for CTSET[142:111] '0' --> Select UTC1 (NRT) utc1_channel_start[31:0] , '1' --> Select nf,msc,ldc0,viss0 master ports (sreq,rreq,creq stall,valid creq)
  [1] CTSET_RT_UTC_OUT — select config for CTSET[238:207] '0' --> Select UTC1 (NRT) utc1_ctset_intr[63:32] , '1' --> Select UTC0 (RT) utc0_ctset_intr[31:0]
  [0] CTSET_RT_UTC_IN — select config for CTSET[174:143] '0' --> Select UTC1 (NRT) utc1_channel_start[63:32] , '1' --> Select UTC0 (RT) utc0_channel_start[31:0]
0x0C misc_status ro
  [10:0] num_rams — Indicates the number of RAMS serviced by the ECC aggregator
0x0C misc_status ro
  fields as misc_status
0x0C CFG — LDC Configuration register. YINT_TYP parameter is used The YINT_TYP parameter only applies to the Y component (Luma). If YINT_TYP = 0, Y pixels are processed using bicubic interpolation, which requires 2 cycles per pixel to process. If YINT_TYP = 1, Y pixels are processed using bilinear interpolation, which requires 1 cycle per pixel to process. This allows a tradeoff between performance versus quality. CbCr (Chroma) pixels are always processed using bilinear interpolation. Thus, the overall performance of pixel processing is based on the Y interpolation type setting.
  [6] YINT_TYP — Interpolation type for Y data. 0: bicubic 1: bilinear
  [1] CLKCG_OVERIDE — Override power saving clock gating inserted by design. '1' -> Allow the clock to be free running (except for gated pixel clock) '0' -> Clock can be gated as planned by the design
0x0C cfg_lse — The CFG_LSE register configures the LSE general hardware modes.
  [8] psa_en — Test mode Output Channel Signature Generation Enable 0: Disable (default) 1: EnableWhen enabled, LSE generates a unique CRC signature for each output channel's frame data at frame completion.
  [4] vm_arb_fixed_mode — VBUSM Arbitration Fixed Mode select 0: Round-Robin Arbitration (default) 1: Fixed-mode Arbitration
0x0C misc_status ro
  fields as misc_status
0x0C cfg_lse — The CFG_LSE register configures the LSE general hardware modes.
  [8] psa_en — Test mode Output Channel Signature Generation Enable 0: Disable (default) 1: EnableWhen enabled, LSE generates a unique CRC signature for each output channel's frame data at frame completion.
  [5] in_ch_sync_mode — Input Channel Transfer Sync Mode (applicable only for VISS) 0: Line Mode (default) 1: Frame ModeWhen set to 0 (Line Mode), LSE waits for a HTS_TSTART on every line reads from SL2. When set to 1 (Frame Mode), LSE waits for the first HTS_TSTART after HTS_INIT to start reading the first line of the frame. Afterward, it continues to read frame data (next lines) from the SL2 without waiting for HTS_TSTART as long as LSE is able to send the data to the core logic without being stalled.
  [4] vm_arb_fixed_mode — VBUSM Arbitration Fixed Mode select 0: Round-Robin Arbitration (default) 1: Fixed-mode Arbitration
  [3:2] loopback_in_ch_sel — Loopback Input Channel Select (applicable only for VISS) 0: Ch0/CAL_Vport_In 1: Ch1 2: Ch2
  [1] loopback_core_en — Functional path (data to HWA core) enable during loopback mode 0: Disable 1: EnableWhen enabled, the loopback-enabled input channel is used also for CORE data input. Otherwise, it is strictly used for the loopback path.
  [0] loopback_en — LSE loopback mode enable 0: Disable 1: EnableWhen enabled, selected input channel data is looped back out to the last (#4) output channel.
0x0C cfg_lse — The CFG_LSE register configures the LSE general hardware modes.
  [8] psa_en — Test mode Output Channel Signature Generation Enable 0: Disable (default) 1: EnableWhen enabled, LSE generates a unique CRC signature for each output channel's frame data at frame completion.
  [4] vm_arb_fixed_mode — VBUSM Arbitration Fixed Mode select 0: Round-Robin Arbitration (default) 1: Fixed-mode Arbitration
  [1] loopback_core_en — Functional path (data to HWA core) enable during loopback mode 0: Disable 1: EnableWhen enabled, the loopback-enabled input channel is used also for CORE data input. Otherwise, it is strictly used for the loopback path.
  [0] loopback_en — LSE loopback mode enable 0: Disable 1: EnableWhen enabled, the second thread's input channel data (middle tap data) is looped back out to the last (#9) output channel.
0x0C cfg_lse — The CFG_LSE register configures the LSE general hardware modes.
  [8] psa_en — Test mode Output Channel Signature Generation Enable 0: Disable (default) 1: EnableWhen enabled, LSE generates a unique CRC signature for each output channel's frame data at frame completion.
  [4] vm_arb_fixed_mode — VBUSM Arbitration Fixed Mode select 0: Round-Robin Arbitration (default) 1: Fixed-mode Arbitration
  [1] loopback_core_en — Functional path (data to HWA core) enable during loopback mode 0: Disable 1: EnableWhen enabled, the loopback-enabled input channel is used also for CORE data input. Otherwise, it is strictly used for the loopback path.
  [0] loopback_en — LSE loopback mode enable 0: Disable 1: EnableWhen enabled, the input channel data (middle tap data) is looped back out to the output channel.
